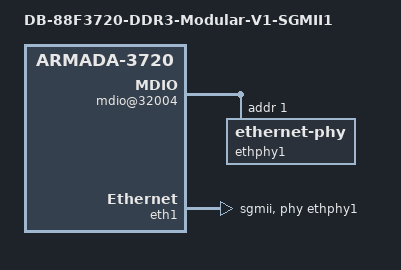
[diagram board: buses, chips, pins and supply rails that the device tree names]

#include "armada-3720-ddr3-db-v1-A.dts"

/* detail board setup:
 * Pcie Jumper slot	:	DB-88F3720-PCIe-mPCIe-Jumper
 * SGMII module slot	:	DB-88F3720-SerDes-Jumper
 * RGMII module slot	:	DB-88F3720-PHY module
 * eMMC slot		:	DB-88F3720-eMMC_NAND module
 * SDIO slot		:	DB-88F3720-SDcard module
 *
 * PHY0 (USB3/SGMII1)	:	SGMII1_Ethernet via PHY (1 Lane)
 * PHY1 (PCIe/SGMII0)	:	PCIe (WiFi via mini_PCIe module)
 * PHY2 (SATA)		:	SATA
 * RGMII		:	Ethernet via PHY (1 Lane)
 * USB2 Port 0		:	USB2 only
 * USB2 Port 1		:	USB2 Host
 * eMMC*		:	eMMC NAND
 * SDIO*		:	SD card
 * BOOT device*		:	SPI Flash
*/

/ {
	model = "DB-88F3720-DDR3-Modular-V1-SGMII1";
	compatible = "marvell,armada-3720-db-v1", "marvell,armada-3720";

	soc {
		internal-regs {
			comphy: comphy@18300 {
				phy1 {
					phy-type = <PHY_TYPE_SGMII1>;
					phy-speed = <PHY_SPEED_1_25G>;
				};
			};
			mdio@32004 {
				#address-cells = <1>;
				#size-cells = <0>;
				ethphy1: ethernet-phy@1 {
					reg = <1>;
				};
			};
			eth1: neta@40000 {
				status = "okay";
				phy-mode = "sgmii";
				phy = <&ethphy1>;
			};
		};
	};
};
